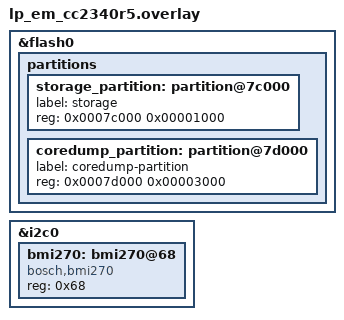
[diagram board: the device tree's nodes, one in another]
/delete-node/ &storage_partition;

&flash0 {
	partitions {
		storage_partition: partition@7c000 {
			label = "storage";
			reg = <0x0007c000 0x00001000>;
		};

		coredump_partition: partition@7d000 {
			label = "coredump-partition";
			reg = <0x0007d000 0x00003000>;
		};
	};
};

&i2c0 {
	bmi270: bmi270@68 {
		compatible = "bosch,bmi270";
		reg = <0x68>;
	};
};
